# PIC18F26Q84 register map
Vendor: Microchip
Registers are 8-bit, read-write, reset 0x0 unless marked. A register's access mark holds for its fields unless they carry their own. Addresses are absolute, and some are shared; only a register's first bit layout is shown; [hi:lo] are bit positions; {n}, {i} and the like mark numbered series.

## can_fd_upb
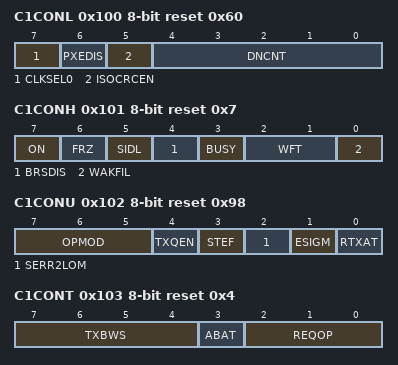
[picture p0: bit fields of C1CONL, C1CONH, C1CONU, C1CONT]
0x100 C1CONL reset 0x60
  [7] CLKSEL0, [6] PXEDIS, [5] ISOCRCEN, [4:0] DNCNT
0x101 C1CONH reset 0x7
  [7] ON, [6] FRZ, [5] SIDL, [4] BRSDIS, [3] BUSY ro, [2:1] WFT, [0] WAKFIL
0x102 C1CONU reset 0x98
  [7:5] OPMOD ro, [4] TXQEN, [3] STEF, [2] SERR2LOM, [1] ESIGM, [0] RTXAT
0x103 C1CONT reset 0x4
  [7:4] TXBWS
  [3] ABAT — (can only be set)
  [2:0] REQOP ro
0x104 C1NBTCFGL reset 0xF
  [6:0] SJW
0x105 C1NBTCFGH reset 0xF
  [6:0] TSEG2
0x106 C1NBTCFGU reset 0x3E
  [7:0] TSEG1
0x107 C1NBTCFGT
  [7:0] BRP
0x108 C1DBTCFGL reset 0x3
  [3:0] SJW
0x109 C1DBTCFGH reset 0x3
  [3:0] TSEG2
0x10A C1DBTCFGU reset 0xE
  [4:0] TSEG1
0x10B C1DBTCFGT
  [7:0] BRP
0x10C C1TDCL
  [5:0] TDCV
0x10D C1TDCH reset 0x10
  [6:0] TDCO
0x10E C1TDCU reset 0x2
  [1:0] TDCMOD
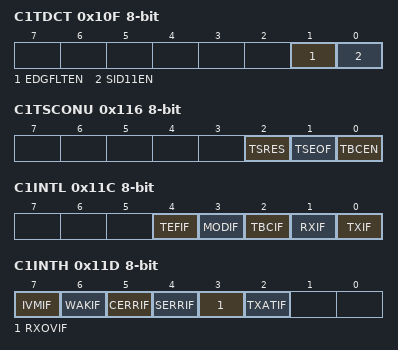
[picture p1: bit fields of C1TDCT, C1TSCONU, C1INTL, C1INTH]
0x10F C1TDCT
  [1] EDGFLTEN, [0] SID11EN
0x110 C1TBCL
  [7:0] TBC
0x111 C1TBCH
  [7:0] TBC
0x112 C1TBCU
  [7:0] TBC
0x113 C1TBCT
  [7:0] TBC
0x114 C1TSCONL
  [7:0] TBCPRE
0x115 C1TSCONH
  [1:0] TBCPRE
0x116 C1TSCONU
  [2] TSRES, [1] TSEOF, [0] TBCEN
0x117 C1TSCONT access not given reset not defined
0x118 C1VECL ro reset 0x40
  [6:0] ICODE
0x119 C1VECH ro
  [4:0] FILHIT
0x11A C1VECU ro reset 0x40
  [6:0] TXCODE
0x11B C1VECT ro reset 0x40
  [6:0] RXCODE
0x11C C1INTL
  [4] TEFIF ro
  [3] MODIF — (can only be cleared)
  [2] TBCIF — (can only be cleared)
  [1] RXIF ro
  [0] TXIF ro
0x11D C1INTH
  [7] IVMIF — (can only be cleared)
  [6] WAKIF — (can only be cleared)
  [5] CERRIF — (can only be cleared)
  [4] SERRIF — (can only be cleared)
  [3] RXOVIF ro
  [2] TXATIF ro
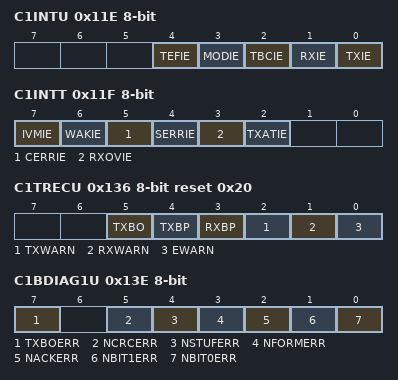
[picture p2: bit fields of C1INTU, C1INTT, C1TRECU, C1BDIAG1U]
0x11E C1INTU
  [4] TEFIE, [3] MODIE, [2] TBCIE, [1] RXIE, [0] TXIE
0x11F C1INTT
  [7] IVMIE, [6] WAKIE, [5] CERRIE, [4] SERRIE, [3] RXOVIE, [2] TXATIE
0x120 C1RXIFL ro
  [7:1] RFIF
0x121 C1RXIFH ro
  [7:0] RFIF
0x122 C1RXIFU ro
  [7:0] RFIF
0x123 C1RXIFT ro
  [7:0] RFIF
0x124 C1TXIFL ro
  [7:0] TFIF
0x125 C1TXIFH ro
  [7:0] TFIF
0x126 C1TXIFU ro
  [7:0] TFIF
0x127 C1TXIFT ro
  [7:0] TFIF
0x128 C1RXOVIFL ro
  [7:1] RFOVIF
0x129 C1RXOVIFH ro
  [7:0] RFOVIF
0x12A C1RXOVIFU ro
  [7:0] RFOVIF
0x12B C1RXOVIFT ro
  [7:0] RFOVIF
0x12C C1TXATIFL ro
  [7:0] TFATIF
0x12D C1TXATIFH ro
  [7:0] TFATIF
0x12E C1TXATIFU ro
  [7:0] TFATIF
0x12F C1TXATIFT ro
  [7:0] TFATIF
0x130 C1TXREQL
  [7:0] TXREQ — (can only be set)
0x131 C1TXREQH
  [7:0] TXREQ — (can only be set)
0x132 C1TXREQU
  [7:0] TXREQ — (can only be set)
0x133 C1TXREQT
  [7:0] TXREQ — (can only be set)
0x134 C1TRECL ro
  [7:0] RERRCNT
0x135 C1TRECH ro
  [7:0] TERRCNT
0x136 C1TRECU reset 0x20
  [5] TXBO, [4] TXBP, [3] RXBP, [2] TXWARN, [1] RXWARN, [0] EWARN
0x137 C1TRECT access not given reset not defined
0x138 C1BDIAG0L
  [7:0] NRERRCNT
0x139 C1BDIAG0H
  [7:0] NTERRCNT
0x13A C1BDIAG0U
  [7:0] DRERRCNT
0x13B C1BDIAG0T
  [7:0] DTERRCNT
0x13C C1BDIAG1L
  [7:0] EFMSGCNT
0x13D C1BDIAG1H
  [7:0] EFMSGCNT
0x13E C1BDIAG1U
  [7] TXBOERR, [5] NCRCERR, [4] NSTUFERR, [3] NFORMERR, [2] NACKERR, [1] NBIT1ERR, [0] NBIT0ERR
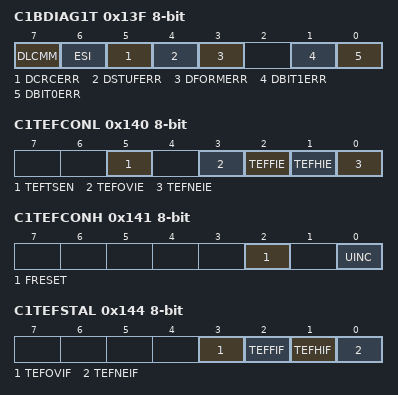
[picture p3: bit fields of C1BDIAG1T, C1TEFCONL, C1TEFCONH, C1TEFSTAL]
0x13F C1BDIAG1T
  [7] DLCMM, [6] ESI, [5] DCRCERR, [4] DSTUFERR, [3] DFORMERR, [1] DBIT1ERR, [0] DBIT0ERR
0x140 C1TEFCONL
  [5] TEFTSEN, [3] TEFOVIE, [2] TEFFIE, [1] TEFHIE, [0] TEFNEIE
0x141 C1TEFCONH
  [2] FRESET — (can only be set)
  [0] UINC — (can only be set)
0x142 C1TEFCONU access not given reset not defined
0x143 C1TEFCONT
  [4:0] FSIZE
0x144 C1TEFSTAL
  [3] TEFOVIF — (can only be set)
  [2] TEFFIF ro
  [1] TEFHIF ro
  [0] TEFNEIF ro
0x145 C1TEFSTAH access not given reset not defined
0x146 C1TEFSTAU access not given reset not defined
0x147 C1TEFSTAT access not given reset not defined
0x148 C1TEFUAL ro
  [7:0] TEFUA
0x149 C1TEFUAH ro
  [7:0] TEFUA
0x14A C1TEFUAU ro
  [7:0] TEFUA
0x14B C1TEFUAT ro
  [7:0] TEFUA
0x14C C1FIFOBAL
  [7:0] FIFOBA
0x14D C1FIFOBAH
  [7:0] FIFOBA
0x14E C1FIFOBAU
  [7:0] FIFOBA
0x14F C1FIFOBAT
  [7:0] FIFOBA
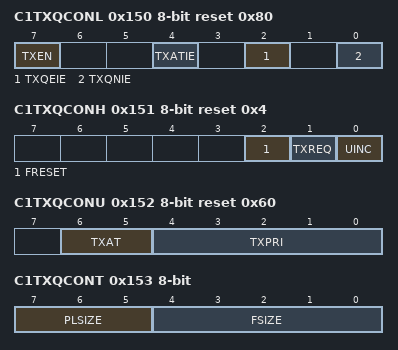
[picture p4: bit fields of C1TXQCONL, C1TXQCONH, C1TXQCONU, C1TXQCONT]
0x150 C1TXQCONL reset 0x80
  [7] TXEN ro, [4] TXATIE, [2] TXQEIE, [0] TXQNIE
0x151 C1TXQCONH reset 0x4
  [2] FRESET — (can only be set)
  [1] TXREQ ro
  [0] UINC — (can only be set)
0x152 C1TXQCONU reset 0x60
  [6:5] TXAT, [4:0] TXPRI
0x153 C1TXQCONT
  [7:5] PLSIZE, [4:0] FSIZE
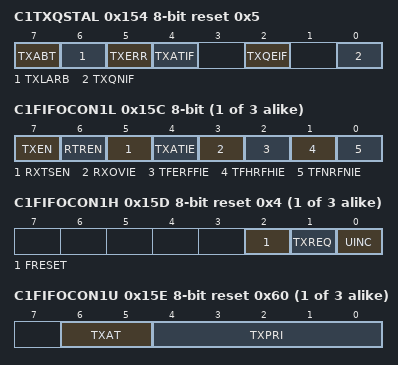
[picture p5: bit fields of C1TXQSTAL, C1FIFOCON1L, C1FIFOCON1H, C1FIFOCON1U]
0x154 C1TXQSTAL reset 0x5
  [7] TXABT ro
  [6] TXLARB ro
  [5] TXERR ro
  [4] TXATIF — (can only be cleared)
  [2] TXQEIF ro
  [0] TXQNIF ro
0x155 C1TXQSTAH ro
  [4:0] TXQCI
0x156 C1TXQSTAU access not given reset not defined
0x157 C1TXQSTAT access not given reset not defined
0x158 C1TXQUAL ro
  [7:0] TXQUA
0x159 C1TXQUAH ro
  [7:0] TXQUA
0x15A C1TXQUAU ro
  [7:0] TXQUA
0x15B C1TXQUAT ro
  [7:0] TXQUA
{0x150+0xC*i} C1FIFOCON{i}L (i=1..3)
  [7] TXEN, [6] RTREN, [5] RXTSEN, [4] TXATIE, [3] RXOVIE, [2] TFERFFIE, [1] TFHRFHIE, [0] TFNRFNIE
{0x151+0xC*i} C1FIFOCON{i}H reset 0x4 (i=1..3)
  [2] FRESET — (can only be set)
  [1] TXREQ
  [0] UINC — (can only be set)
{0x152+0xC*i} C1FIFOCON{i}U reset 0x60 (i=1..3)
  [6:5] TXAT, [4:0] TXPRI
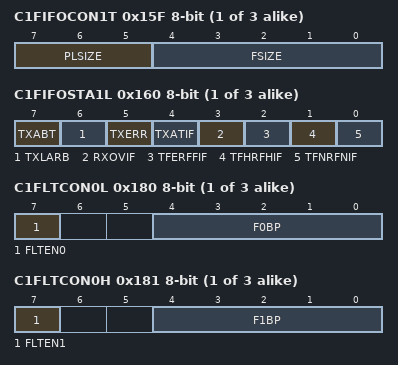
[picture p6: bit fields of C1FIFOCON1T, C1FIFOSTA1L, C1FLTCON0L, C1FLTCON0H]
{0x153+0xC*i} C1FIFOCON{i}T (i=1..3)
  [7:5] PLSIZE, [4:0] FSIZE
{0x154+0xC*i} C1FIFOSTA{i}L (i=1..3)
  [7] TXABT ro
  [6] TXLARB ro
  [5] TXERR ro
  [4] TXATIF — (can only be set)
  [3] RXOVIF — (can only be set)
  [2] TFERFFIF ro
  [1] TFHRFHIF ro
  [0] TFNRFNIF ro
{0x155+0xC*i} C1FIFOSTA{i}H ro (i=1..3)
  [4:0] FIFOCI
{0x156+0xC*i} C1FIFOSTA{i}U access not given reset not defined (i=1..3)
{0x157+0xC*i} C1FIFOSTA{i}T access not given reset not defined (i=1..3)
{0x158+0xC*i} C1FIFOUA{i}L ro (i=1..3)
  [7:0] FIFOUA
{0x159+0xC*i} C1FIFOUA{i}H ro (i=1..3)
  [7:0] FIFOUA
{0x15A+0xC*i} C1FIFOUA{i}U ro (i=1..3)
  [7:0] FIFOUA
{0x15B+0xC*i} C1FIFOUA{i}T ro (i=1..3)
  [7:0] FIFOUA
{0x180+4i} C1FLTCON{i}L (i=0..2)
  [7] FLTEN{4i}, [4:0] F{4i}BP
{0x181+4i} C1FLTCON{i}H (i=0..2)
  [7] FLTEN{4i+1}, [4:0] F{4i+1}BP
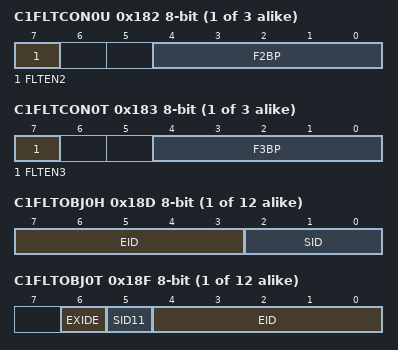
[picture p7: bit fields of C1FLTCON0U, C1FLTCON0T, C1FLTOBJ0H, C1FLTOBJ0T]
{0x182+4i} C1FLTCON{i}U (i=0..2)
  [7] FLTEN{4i+2}, [4:0] F{4i+2}BP
{0x183+4i} C1FLTCON{i}T (i=0..2)
  [7] FLTEN{4i+3}, [4:0] F{4i+3}BP
{0x18C+8i} C1FLTOBJ{i}L (i=0..11)
  [7:0] SID
{0x18D+8i} C1FLTOBJ{i}H (i=0..11)
  [7:3] EID, [2:0] SID
{0x18E+8i} C1FLTOBJ{i}U (i=0..11)
  [7:0] EID
{0x18F+8i} C1FLTOBJ{i}T (i=0..11)
  [6] EXIDE, [5] SID11, [4:0] EID
{0x190+8i} C1MASK{i}L (i=0..11)
  [7:0] MSID
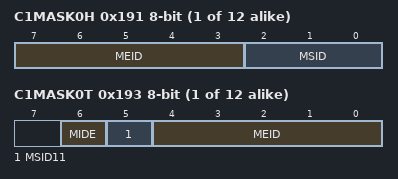
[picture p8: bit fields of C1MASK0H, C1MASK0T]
{0x191+8i} C1MASK{i}H (i=0..11)
  [7:3] MEID, [2:0] MSID
{0x192+8i} C1MASK{i}U (i=0..11)
  [7:0] MEID
{0x193+8i} C1MASK{i}T (i=0..11)
  [6] MIDE, [5] MSID11, [4:0] MEID
